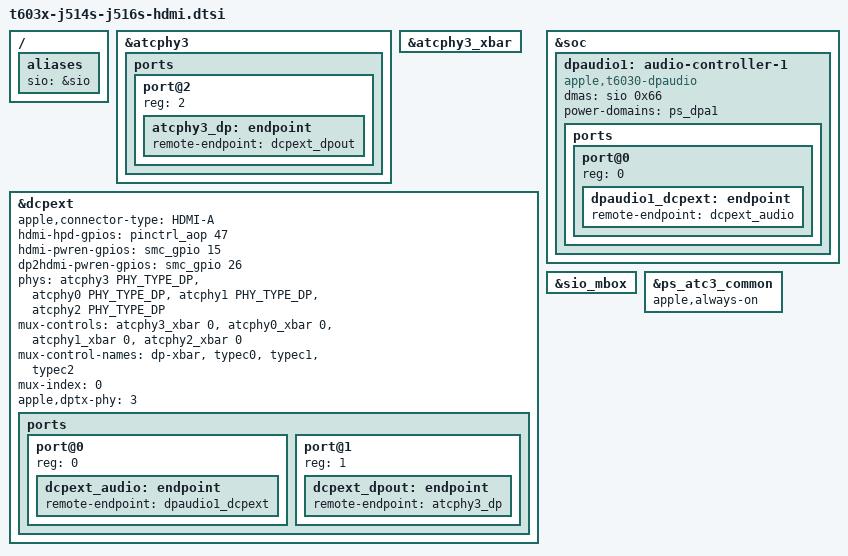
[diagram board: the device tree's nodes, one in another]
// SPDX-License-Identifier: GPL-2.0+ OR MIT
/*
 * HDMI port of the t6030 (M3 Pro) MacBook Pros j514s and j516s.
 *
 * The first external display processor drives ATC3 as a four-lane
 * DisplayPort PHY through the ATC3 display crossbar into an on-board
 * DP-to-HDMI converter, as on the M1/M2 Pro and Max MacBook Pros. The
 * converter has its own power enable, the HDMI port another one, and the
 * port's hotplug signal comes in on an AOP GPIO.
 *
 * The processor stays a hybrid pipeline: while no HDMI display is attached
 * it can still be lent to a USB-C port.
 *
 * The HDMI port's audio is the processor's audio service with DPA1, the
 * DisplayPort audio interface its port@0 links (no AP-side registers): SIO
 * channel 0x66 carries the samples, as on the M1 Pro/Max HDMI port. The
 * loader reserves the SIO firmware and enables the SIO with its parameters.
 */

/ {
	aliases {
		/* The boot loader looks the SIO up by this alias. */
		sio = &sio;
	};
};

&atcphy3 {
	status = "okay";

	ports {
		#address-cells = <1>;
		#size-cells = <0>;

		port@2 {
			reg = <2>;
			atcphy3_dp: endpoint {
				remote-endpoint = <&dcpext_dpout>;
			};
		};
	};
};

&atcphy3_xbar {
	status = "okay";
};

&dcpext {
	apple,connector-type = "HDMI-A";

	/* HDMI HPD, also used as the hotplug interrupt */
	hdmi-hpd-gpios = <&pinctrl_aop 47 GPIO_ACTIVE_HIGH>;
	hdmi-pwren-gpios = <&smc_gpio 15 GPIO_ACTIVE_HIGH>;
	dp2hdmi-pwren-gpios = <&smc_gpio 26 GPIO_ACTIVE_HIGH>;

	phys = <&atcphy3 PHY_TYPE_DP>, <&atcphy0 PHY_TYPE_DP>,
	       <&atcphy1 PHY_TYPE_DP>, <&atcphy2 PHY_TYPE_DP>;
	phy-names = "dp-phy", "typec0", "typec1", "typec2";
	mux-controls = <&atcphy3_xbar 0>, <&atcphy0_xbar 0>,
		       <&atcphy1_xbar 0>, <&atcphy2_xbar 0>;
	mux-control-names = "dp-xbar", "typec0", "typec1", "typec2";
	mux-index = <0>;
	apple,dptx-phy = <3>;

	ports {
		#address-cells = <1>;
		#size-cells = <0>;

		port@0 {
			reg = <0>;
			dcpext_audio: endpoint {
				remote-endpoint = <&dpaudio1_dcpext>;
			};
		};

		port@1 {
			reg = <1>;
			dcpext_dpout: endpoint {
				remote-endpoint = <&atcphy3_dp>;
			};
		};
	};
};

/* DPA1: the HDMI port's DisplayPort audio, SIO channel 0x66. */
&soc {
	dpaudio1: audio-controller-1 {
		compatible = "apple,t6030-dpaudio", "apple,dpaudio";
		dmas = <&sio 0x66>;
		dma-names = "tx";
		power-domains = <&ps_dpa1>;

		ports {
			#address-cells = <1>;
			#size-cells = <0>;

			port@0 {
				reg = <0>;
				dpaudio1_dcpext: endpoint {
					remote-endpoint = <&dcpext_audio>;
				};
			};
		};
	};
};

/* The SIO's mailbox; the boot loader enables the SIO with its firmware. */
&sio_mbox {
	status = "okay";
};

/*
 * ATC3 has no USB consumer that would hold its common block on, so across
 * system sleep it would power down and lose the HDMI PHY state.
 */
&ps_atc3_common {
	apple,always-on;
};
